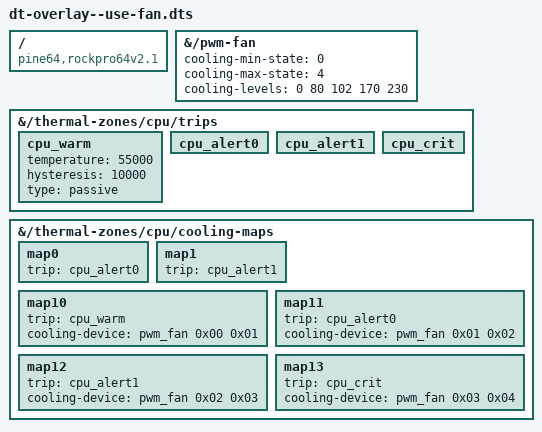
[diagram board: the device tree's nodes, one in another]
/dts-v1/;
/plugin/;

/ {
  compatible = "pine64,rockpro64v2.1", "pine64,rockpro64";

  // thermal-zone trips [°C]
  // name          4.19       mainline
  // cpu_alert0    80_000     70_000
  // cpu_alert1    95_000     75_000
  // cpu_crit      100_000    95_000
  //
  // 4.19 is from this kernel: https://github.com/BBBSnowball/nixos-installer-rockpro64/blob/master/linux-rock64/4.19.nix
  // mainline is from version 5.9.16.
  //
  // 4.19 slows down one CPU for the first trip and two for the second one. It also enables the fan.
  // mainline slows down two CPUs for the first trip and all of them for the second trip.
  //
  // This overlay implements the following mix of those:
  // - Use temperatures and throttling of mainline.
  // - Enable the fan at those temperatures.
  // - Enable the fan at slow speed if temperature is above 50°C.

  fragment@0 {
    target-path = "/pwm-fan";
    pwm_fan: __overlay__ {
      #cooling-cells = <0x02>;
      cooling-min-state = <0>;
      cooling-max-state = <4>;
      cooling-levels = <0 80 102 170 230>;
    };
  };

  fragment@1 {
    target-path = "/thermal-zones/cpu/trips";
    __overlay__ {
      cpu_warm: cpu_warm {
        temperature = <55000>;
        hysteresis = <10000>;
        type = "passive";
      };
      cpu_alert0: cpu_alert0 {};
      cpu_alert1: cpu_alert1 {};
      cpu_crit:   cpu_crit   {};
    };
  };

  fragment@2 {
    target-path = "/thermal-zones/cpu/cooling-maps";
    __overlay__ {
      // We are redefining the phandles of existing trip points -> fix references to them
      map0 {
        trip = <&cpu_alert0>;
      };
      map1 {
        trip = <&cpu_alert1>;
      };

      // Add new maps for the fan.
      map10 {
        trip = <&cpu_warm>;
        cooling-device = <&pwm_fan 0x00 0x01>;
      };
      map11 {
        trip = <&cpu_alert0>;
        cooling-device = <&pwm_fan 0x01 0x02>;
      };
      map12 {
        trip = <&cpu_alert1>;
        cooling-device = <&pwm_fan 0x02 0x03>;
      };
      map13 {
        trip = <&cpu_crit>;
        cooling-device = <&pwm_fan 0x03 0x04>;
      };
    };
  };
};
